VERSION ""

NS_ :

BS_:

BU_: XXX

BO_ 2 STEERING: 8 XXX
 SG_ SteeringAngle : 7|16@0- (0.1,0) [-600|600] "" XXX

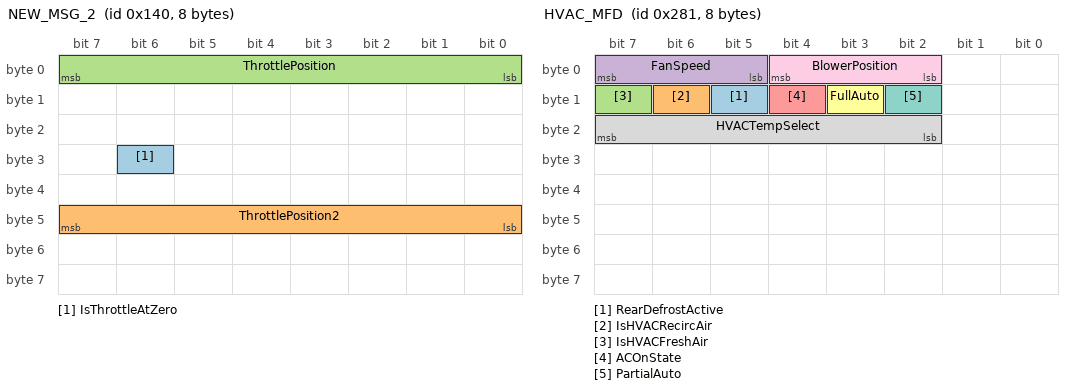
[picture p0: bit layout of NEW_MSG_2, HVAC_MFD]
BO_ 320 NEW_MSG_2: 8 XXX
 SG_ IsThrottleAtZero : 30|1@0+ (1,0) [0|1] "" XXX
 SG_ ThrottlePosition2 : 47|8@0+ (1,0) [0|255] "" XXX
 SG_ ThrottlePosition : 7|8@0+ (1,0) [0|255] "" XXX

BO_ 340 NEW_MSG_3: 8 XXX
 SG_ KeyInIgnition : 4|1@0+ (1,0) [0|1] "" XXX
 SG_ BrakePedalPressed : 50|1@0+ (1,0) [0|1] "" XXX

BO_ 641 HVAC_MFD: 8 XXX
 SG_ RearDefrostActive : 13|1@0+ (1,0) [0|1] "" XXX
 SG_ IsHVACRecircAir : 14|1@0+ (1,0) [0|1] "" XXX
 SG_ IsHVACFreshAir : 15|1@0+ (1,0) [0|1] "" XXX
 SG_ FanSpeed : 7|3@0+ (1,0) [0|18] "" XXX
 SG_ ACOnState : 12|1@0+ (1,0) [0|1] "" XXX
 SG_ FullAuto : 11|1@0+ (1,0) [0|1] "" XXX
 SG_ PartialAuto : 10|1@0+ (1,0) [0|1] "" XXX
 SG_ HVACTempSelect : 23|6@0+ (1,56) [60|90] "" XXX
 SG_ BlowerPosition : 4|3@0+ (1,0) [0|18] "" XXX

BO_ 886 DASH_DIM_LEVEL: 8 XXX
 SG_ DashDimLvl : 7|8@0+ (0.028,0) [0|255] "" XXX

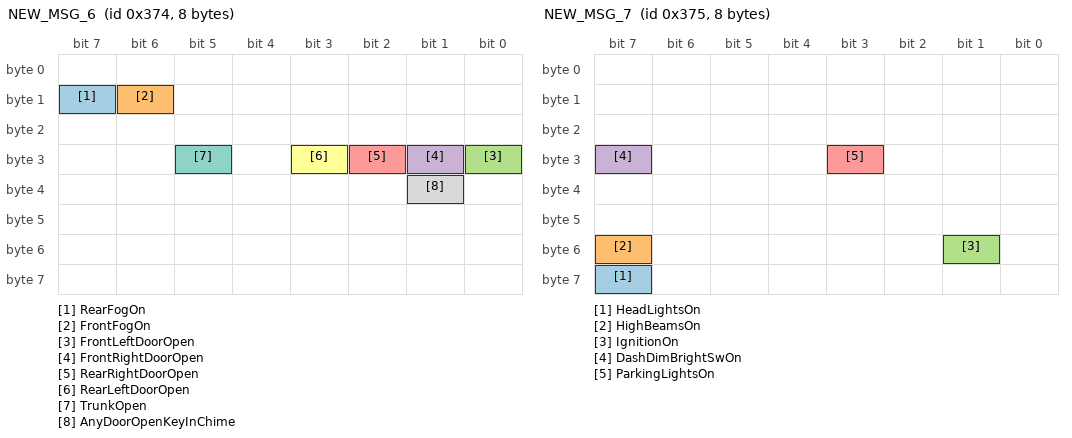
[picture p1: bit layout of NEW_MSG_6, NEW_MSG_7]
BO_ 884 NEW_MSG_6: 8 XXX
 SG_ RearFogOn : 15|1@0+ (1,0) [0|1] "" XXX
 SG_ FrontFogOn : 14|1@0+ (1,0) [0|1] "" XXX
 SG_ FrontLeftDoorOpen : 24|1@0+ (1,0) [0|1] "" XXX
 SG_ FrontRightDoorOpen : 25|1@0+ (1,0) [0|1] "" XXX
 SG_ RearRightDoorOpen : 26|1@0+ (1,0) [0|1] "" XXX
 SG_ RearLeftDoorOpen : 27|1@0+ (1,0) [0|1] "" XXX
 SG_ TrunkOpen : 29|1@0+ (1,0) [0|1] "" XXX
 SG_ AnyDoorOpenKeyInChime : 33|1@0+ (1,0) [0|1] "" XXX

BO_ 885 NEW_MSG_7: 8 XXX
 SG_ HeadLightsOn : 63|1@0+ (1,0) [0|1] "" XXX
 SG_ HighBeamsOn : 55|1@0+ (1,0) [0|1] "" XXX
 SG_ IgnitionOn : 49|1@0+ (1,0) [0|1] "" XXX
 SG_ DashDimBrightSwOn : 31|1@0+ (1,0) [0|1] "" XXX
 SG_ ParkingLightsOn : 27|1@0+ (1,0) [0|1] "" XXX

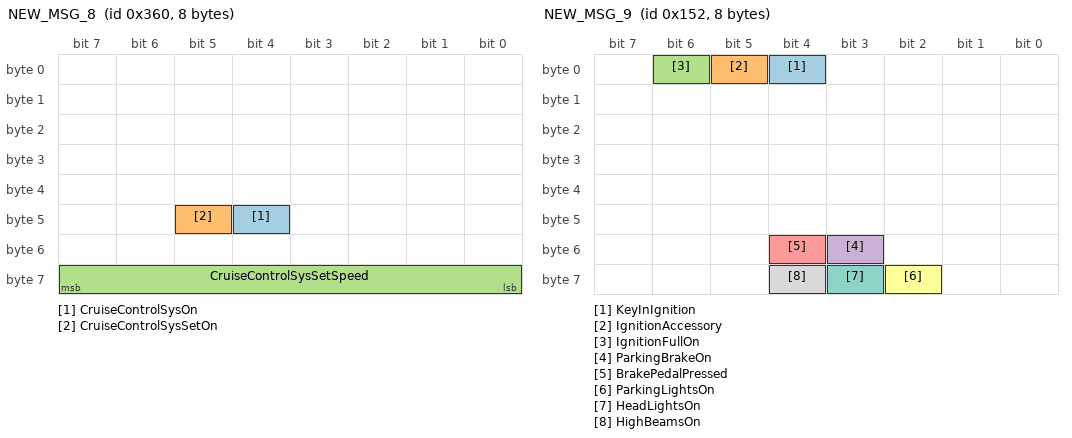
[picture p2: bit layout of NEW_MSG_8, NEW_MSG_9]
BO_ 864 NEW_MSG_8: 8 XXX
 SG_ CruiseControlSysOn : 44|1@0+ (1,0) [0|1] "" XXX
 SG_ CruiseControlSysSetOn : 45|1@0+ (1,0) [0|1] "" XXX
 SG_ CruiseControlSysSetSpeed : 56|8@1+ (1,0) [0|255] "" XXX

BO_ 338 NEW_MSG_9: 8 XXX
 SG_ KeyInIgnition : 4|1@0+ (1,0) [0|1] "" XXX
 SG_ IgnitionAccessory : 5|1@0+ (1,0) [0|1] "" XXX
 SG_ IgnitionFullOn : 6|1@0+ (1,0) [0|1] "" XXX
 SG_ ParkingBrakeOn : 51|1@0+ (1,0) [0|1] "" XXX
 SG_ BrakePedalPressed : 52|1@0+ (1,0) [0|1] "" XXX
 SG_ ParkingLightsOn : 58|1@0+ (1,0) [0|1] "" XXX
 SG_ HeadLightsOn : 59|1@0+ (1,0) [0|1] "" XXX
 SG_ HighBeamsOn : 60|1@0+ (1,0) [0|1] "" XXX

BO_ 209 NEW_MSG_10: 8 XXX
 SG_ VehicleSpeedKPH : 0|16@1+ (0.05625,0) [0|140] "" XXX
 SG_ BrakePedalPressure : 23|8@0+ (1,0) [0|255] "" XXX

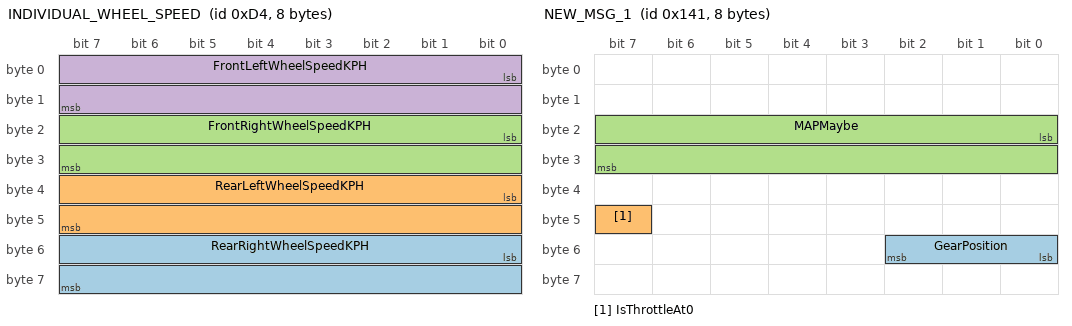
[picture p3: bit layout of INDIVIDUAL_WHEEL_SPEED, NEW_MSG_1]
BO_ 212 INDIVIDUAL_WHEEL_SPEED: 8 XXX
 SG_ RearRightWheelSpeedKPH : 48|16@1+ (0.05625,0) [0|140] "" XXX
 SG_ RearLeftWheelSpeedKPH : 32|16@1+ (0.05625,0) [0|140] "" XXX
 SG_ FrontRightWheelSpeedKPH : 16|16@1+ (0.05625,0) [0|140] "" XXX
 SG_ FrontLeftWheelSpeedKPH : 0|16@1+ (0.05625,0) [0|140] "" XXX

BO_ 321 NEW_MSG_1: 8 XXX
 SG_ GearPosition : 48|3@1+ (1,0) [0|7] "" XXX
 SG_ IsThrottleAt0 : 47|1@0+ (1,0) [0|1] "" XXX
 SG_ MAPMaybe : 16|16@1+ (0.1,0) [-200|65535] "" XXX

BO_ 208 SteeringAngleSensor: 8 XXX
 SG_ SteeringAngle : 0|16@1+ (0.1,0) [-500|500] "" XXX
 SG_ State : 63|8@0+ (1,0) [0|255] "" XXX

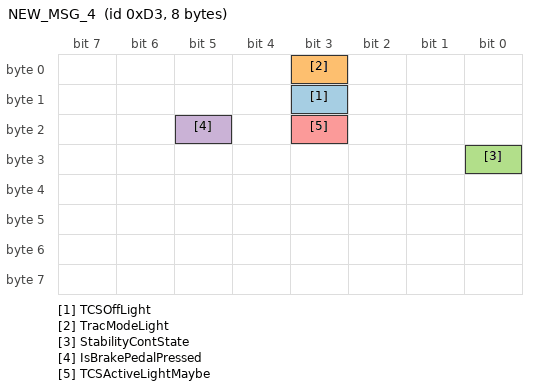
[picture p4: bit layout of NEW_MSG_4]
BO_ 211 NEW_MSG_4: 8 XXX
 SG_ TCSOffLight : 11|1@0+ (1,0) [0|1] "" XXX
 SG_ TracModeLight : 3|1@0+ (1,0) [0|1] "" XXX
 SG_ StabilityContState : 24|1@0+ (1,0) [0|1] "" XXX
 SG_ IsBrakePedalPressed : 21|1@0+ (1,0) [0|1] "" XXX
 SG_ TCSActiveLightMaybe : 19|1@0+ (1,0) [0|1] "" XXX

BO_ 642 NEW_MSG_5: 8 XXX
 SG_ LeftTurnSignal : 44|1@0+ (1,0) [0|1] "" XXX
 SG_ RightTurnSignal : 45|1@0+ (1,0) [0|1] "" XXX

BO_ 210 NEW_MSG_11: 8 XXX

BO_ 324 NEW_MSG_12: 8 XXX

BO_ 977 NEW_MSG_13: 8 XXX

CM_ SG_ 641 HVACTempSelect "Temp mostly correct except HI and LO";
CM_ SG_ 886 DashDimLvl "Factor incorrect";
CM_ SG_ 208 SteeringAngle "Scaling incorrect";
CM_ SG_ 208 State "FF is off and 00 is on maybe";
